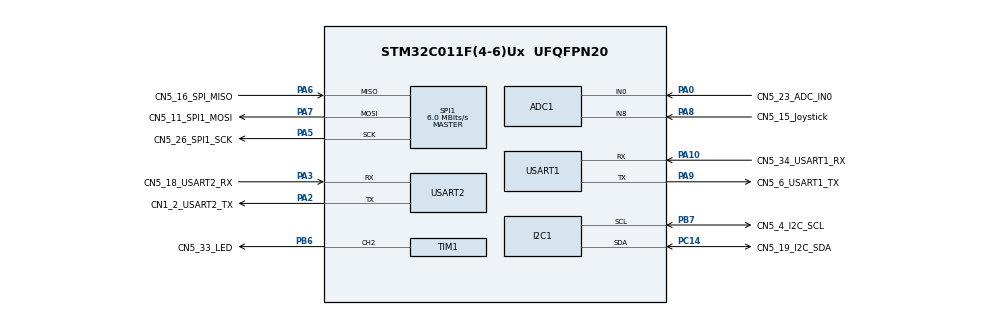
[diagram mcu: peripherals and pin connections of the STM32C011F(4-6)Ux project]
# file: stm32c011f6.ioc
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ADC1.Channel-0\#ChannelRegularConversion=ADC_CHANNEL_8
ADC1.Channel-1\#ChannelRegularConversion=ADC_CHANNEL_0
ADC1.ClockPrescaler=ADC_CLOCK_SYNC_PCLK_DIV2
ADC1.NbrOfConversion=2
ADC1.NbrOfConversionFlag=1
ADC1.Rank-0\#ChannelRegularConversion=1
ADC1.Rank-1\#ChannelRegularConversion=2
ADC1.SamplingTime-0\#ChannelRegularConversion=ADC_SAMPLINGTIME_COMMON_1
ADC1.SamplingTime-1\#ChannelRegularConversion=ADC_SAMPLINGTIME_COMMON_1
ADC1.SelectedChannel=ADC_CHANNEL_0|ADC_CHANNEL_8
ADC1.master=1
Dma.ADC1.0.Direction=DMA_PERIPH_TO_MEMORY
Dma.ADC1.0.EventEnable=DISABLE
Dma.ADC1.0.Instance=DMA1_Channel1
Dma.ADC1.0.MemDataAlignment=DMA_MDATAALIGN_WORD
Dma.ADC1.0.MemInc=DMA_MINC_ENABLE
Dma.ADC1.0.Mode=DMA_NORMAL
Dma.ADC1.0.PeriphDataAlignment=DMA_PDATAALIGN_HALFWORD
Dma.ADC1.0.PeriphInc=DMA_PINC_DISABLE
Dma.ADC1.0.Polarity=HAL_DMAMUX_REQ_GEN_RISING
Dma.ADC1.0.Priority=DMA_PRIORITY_LOW
Dma.ADC1.0.RequestNumber=1
Dma.ADC1.0.SignalID=NONE
Dma.ADC1.0.SyncEnable=DISABLE
Dma.ADC1.0.SyncPolarity=HAL_DMAMUX_SYNC_NO_EVENT
Dma.ADC1.0.SyncRequestNumber=1
Dma.ADC1.0.SyncSignalID=NONE
Dma.Request0=ADC1
I2C1.Timing=0x20303E5D
Mcu.Family=STM32C0
Mcu.Name=STM32C011F(4-6)Ux
Mcu.Package=UFQFPN20
NVIC.ADC1_IRQn=true\:0\:0\:false\:false\:true\:true\:true\:true
NVIC.DMA1_Channel1_IRQn=true\:0\:0\:false\:false\:true\:false\:true\:true
PA0.GPIO_Label=CN5_23_ADC_IN0
PA0.Mode=IN0
PA0.Signal=ADC1_IN0
PA10\ [PA12].GPIO_Label=CN5_34_USART1_RX
PA10\ [PA12].Mode=Asynchronous
PA10\ [PA12].Signal=USART1_RX
PA13.Mode=Serial_Wire
PA13.Signal=DEBUG_SWDIO
PA14-BOOT0.Mode=Serial_Wire
PA14-BOOT0.Signal=DEBUG_SWCLK
PA2.GPIO_Label=CN1_2_USART2_TX
PA2.Mode=Asynchronous
PA2.Signal=USART2_TX
PA3.GPIO_Label=CN5_18_USART2_RX
PA3.Mode=Asynchronous
PA3.Signal=USART2_RX
PA5.GPIO_Label=CN5_26_SPI1_SCK
PA5.Mode=Full_Duplex_Master
PA5.Signal=SPI1_SCK
PA6.GPIO_Label=CN5_16_SPI_MISO
PA6.Mode=Full_Duplex_Master
PA6.Signal=SPI1_MISO
PA7.GPIO_Label=CN5_11_SPI1_MOSI
PA7.Mode=Full_Duplex_Master
PA7.Signal=SPI1_MOSI
PA8.GPIO_Label=CN5_15_Joystick
PA8.Mode=IN8
PA8.Signal=ADC1_IN8
PA9\ [PA11].GPIO_Label=CN5_6_USART1_TX
PA9\ [PA11].Mode=Asynchronous
PA9\ [PA11].Signal=USART1_TX
PB6.GPIO_Label=CN5_33_LED
PB6.Signal=S_TIM1_CH2
PB7.GPIO_Label=CN5_4_I2C_SCL
PB7.Mode=I2C
PB7.Signal=I2C1_SCL
PC14-OSCX_IN\ (PC14).GPIO_Label=CN5_19_I2C_SDA
PC14-OSCX_IN\ (PC14).Mode=I2C
PC14-OSCX_IN\ (PC14).Signal=I2C1_SDA
ProjectManager.HeapSize=0x200
ProjectManager.StackSize=0x400
ProjectManager.TargetToolchain=Makefile
RCC.ADCFreq_Value=48000000
RCC.AHBFreq_Value=48000000
RCC.CortexFreq_Value=48000000
RCC.EXTERNAL_CLOCK_VALUE=12288000
RCC.HCLKFreq_Value=48000000
RCC.HSE_VALUE=8000000
RCC.HSISYSCLKDivider=RCC_HSI_DIV1
RCC.HSI_VALUE=48000000
RCC.LSE_VALUE=32768
RCC.SYSCLKFreq_VALUE=48000000
SH.S_TIM1_CH2.0=TIM1_CH2,PWM Generation2 CH2
SPI1.BaudRatePrescaler=SPI_BAUDRATEPRESCALER_8
SPI1.CalculateBaudRate=6.0 MBits/s
SPI1.Direction=SPI_DIRECTION_2LINES
SPI1.Mode=SPI_MODE_MASTER
SPI1.NSSPMode=SPI_NSS_PULSE_DISABLE
SPI1.TIMode=SPI_TIMODE_DISABLE
SPI1.VirtualType=VM_MASTER
TIM1.AutoReloadPreload=TIM_AUTORELOAD_PRELOAD_ENABLE
TIM1.Channel-PWM\ Generation2\ CH2=TIM_CHANNEL_2
TIM1.OCIdleState_2=TIM_OCIDLESTATE_SET
TIM1.Period=4095
TIM1.Prescaler=48
USART1.VirtualMode-Asynchronous=VM_ASYNC
USART2.VirtualMode-Asynchronous=VM_ASYNC
VP_SYS_VS_PINREMAP.Mode=PINREMAP
VP_SYS_VS_PINREMAP_10_12.Mode=PINREMAP_10_12
VP_TIM1_VS_ClockSourceINT.Mode=Internal
board=STM32C0116-DK

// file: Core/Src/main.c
/* USER CODE BEGIN Header */
/**
  ******************************************************************************
  * @file           : main.c
  * @brief          : Main program body
  ******************************************************************************
  * @attention
  *
  * Copyright (c) 2023 STMicroelectronics.
  * All rights reserved.
  *
  * This software is licensed under terms that can be found in the LICENSE file
  * in the root directory of this software component.
  * If no LICENSE file comes with this software, it is provided AS-IS.
  *
  ******************************************************************************
  */
/* USER CODE END Header */
#include "main.h"
#include "adc.h"
#include "dma.h"
#include "i2c.h"
#include "spi.h"
#include "tim.h"
#include "usart.h"
#include "gpio.h"

/* USER CODE BEGIN Includes */
#include "Application.hpp"
/* USER CODE END Includes */

void SystemClock_Config(void);

int main(void)
{

  /* MCU Configuration--------------------------------------------------------*/

  /* Reset of all peripherals, Initializes the Flash interface and the Systick. */
  HAL_Init();

  /* Configure the system clock */
  SystemClock_Config();

  /* Initialize all configured peripherals */
  MX_GPIO_Init();
  MX_DMA_Init();
  MX_SPI1_Init();
  MX_USART1_UART_Init();
  MX_USART2_UART_Init();
  MX_I2C1_Init();
  MX_ADC1_Init();
  MX_TIM1_Init();
  /* USER CODE BEGIN 2 */
  application_init();
  /* USER CODE END 2 */

  /* Infinite loop */
  /* USER CODE BEGIN WHILE */
  while (1)
  {
    application_run();
    /* USER CODE END WHILE */

  }
}

void SystemClock_Config(void)
{
  RCC_OscInitTypeDef RCC_OscInitStruct = {0};
  RCC_ClkInitTypeDef RCC_ClkInitStruct = {0};

  /** Initializes the RCC Oscillators according to the specified parameters
  * in the RCC_OscInitTypeDef structure.
  */
  RCC_OscInitStruct.OscillatorType = RCC_OSCILLATORTYPE_HSI;
  RCC_OscInitStruct.HSIState = RCC_HSI_ON;
  RCC_OscInitStruct.HSIDiv = RCC_HSI_DIV1;
  RCC_OscInitStruct.HSICalibrationValue = RCC_HSICALIBRATION_DEFAULT;
  if (HAL_RCC_OscConfig(&RCC_OscInitStruct) != HAL_OK)
  {
    Error_Handler();
  }

  /** Initializes the CPU, AHB and APB buses clocks
  */
  RCC_ClkInitStruct.ClockType = RCC_CLOCKTYPE_HCLK|RCC_CLOCKTYPE_SYSCLK
                              |RCC_CLOCKTYPE_PCLK1;
  RCC_ClkInitStruct.SYSCLKSource = RCC_SYSCLKSOURCE_HSI;
  RCC_ClkInitStruct.SYSCLKDivider = RCC_SYSCLK_DIV1;
  RCC_ClkInitStruct.AHBCLKDivider = RCC_HCLK_DIV1;
  RCC_ClkInitStruct.APB1CLKDivider = RCC_APB1_DIV1;

  if (HAL_RCC_ClockConfig(&RCC_ClkInitStruct, FLASH_LATENCY_1) != HAL_OK)
  {
    Error_Handler();
  }
}

void Error_Handler(void)
{
  __disable_irq();
  while (1)
  {
  }
}
